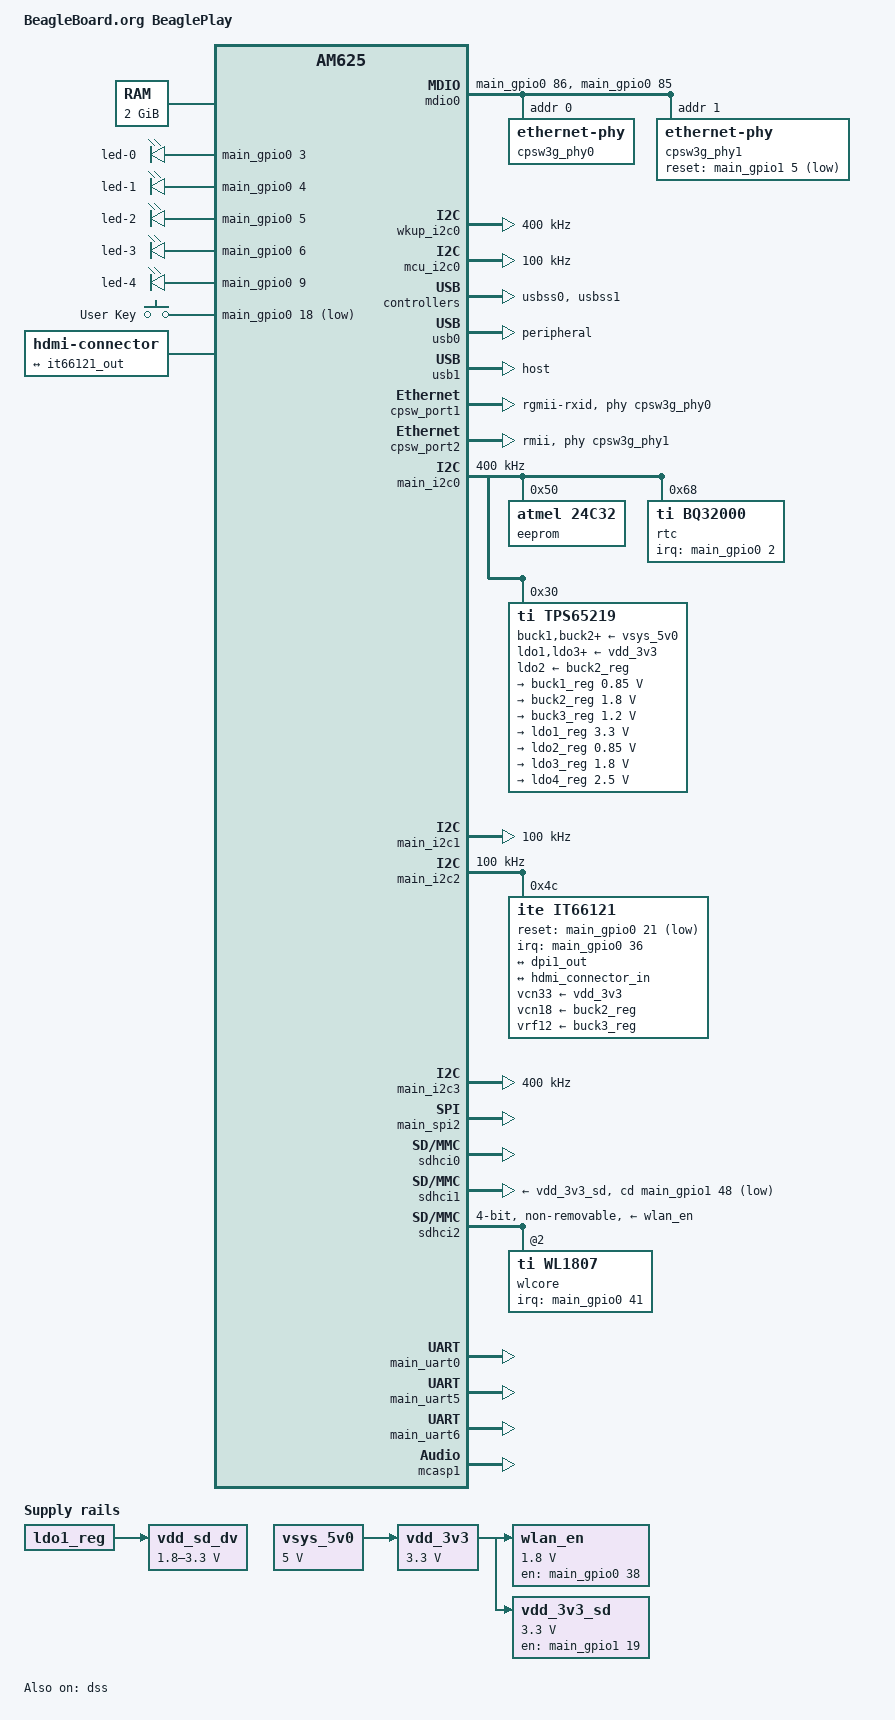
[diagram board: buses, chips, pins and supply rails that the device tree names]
/dts-v1/;
#include <dt-bindings/leds/common.h>
#include <dt-bindings/gpio/gpio.h>
#include <dt-bindings/input/input.h>
#include "k3-am625.dtsi"
/ {
	compatible = "beagle,am625-beagleplay", "ti,am625";
	model = "BeagleBoard.org BeaglePlay";
	aliases {
		ethernet0 = &cpsw_port1;
		ethernet1 = &cpsw_port2;
		gpio0 = &main_gpio0;
		gpio1 = &main_gpio1;
		gpio2 = &mcu_gpio0;
		i2c0 = &main_i2c0;
		i2c1 = &main_i2c1;
		i2c2 = &main_i2c2;
		i2c3 = &main_i2c3;
		i2c4 = &wkup_i2c0;
		i2c5 = &mcu_i2c0;
		mdio-gpio0 = &mdio0;
		mmc0 = &sdhci0;
		mmc1 = &sdhci1;
		mmc2 = &sdhci2;
		rtc0 = &rtc;
		serial0 = &main_uart5;
		serial1 = &main_uart6;
		serial2 = &main_uart0;
		usb0 = &usb0;
		usb1 = &usb1;
	};
	chosen {
		stdout-path = "serial2:115200n8";
	};
	memory@80000000 {
		device_type = "memory";
		reg = <0x00000000 0x80000000 0x00000000 0x80000000>;
	};
	reserved-memory {
		#address-cells = <2>;
		#size-cells = <2>;
		ranges;
		ramoops: ramoops@9ca00000 {
			compatible = "ramoops";
			reg = <0x00 0x9ca00000 0x00 0x00100000>;
			record-size = <0x8000>;
			console-size = <0x8000>;
			ftrace-size = <0x00>;
			pmsg-size = <0x8000>;
		};
		secure_tfa_ddr: tfa@9e780000 {
			reg = <0x00 0x9e780000 0x00 0x80000>;
			no-map;
		};
		secure_ddr: optee@9e800000 {
			reg = <0x00 0x9e800000 0x00 0x01800000>;
			no-map;
		};
		wkup_r5fss0_core0_dma_memory_region: r5f-dma-memory@9db00000 {
			compatible = "shared-dma-pool";
			reg = <0x00 0x9db00000 0x00 0xc00000>;
			no-map;
		};
	};
	vsys_5v0: regulator-1 {
		compatible = "regulator-fixed";
		regulator-name = "vsys_5v0";
		regulator-min-microvolt = <5000000>;
		regulator-max-microvolt = <5000000>;
		regulator-always-on;
		regulator-boot-on;
	};
	vdd_3v3: regulator-2 {
		compatible = "regulator-fixed";
		regulator-name = "vdd_3v3";
		regulator-min-microvolt = <3300000>;
		regulator-max-microvolt = <3300000>;
		vin-supply = <&vsys_5v0>;
		regulator-always-on;
		regulator-boot-on;
	};
	wlan_en: regulator-3 {
		compatible = "regulator-fixed";
		regulator-name = "wlan_en";
		regulator-min-microvolt = <1800000>;
		regulator-max-microvolt = <1800000>;
		enable-active-high;
		regulator-always-on;
		vin-supply = <&vdd_3v3>;
		gpio = <&main_gpio0 38 GPIO_ACTIVE_HIGH>;
		pinctrl-names = "default";
		pinctrl-0 = <&wifi_en_pins_default>;
	};
	vdd_3v3_sd: regulator-4 {
		pinctrl-names = "default";
		pinctrl-0 = <&vdd_3v3_sd_pins_default>;
		compatible = "regulator-fixed";
		regulator-name = "vdd_3v3_sd";
		regulator-min-microvolt = <3300000>;
		regulator-max-microvolt = <3300000>;
		enable-active-high;
		regulator-always-on;
		vin-supply = <&vdd_3v3>;
		gpio = <&main_gpio1 19 GPIO_ACTIVE_HIGH>;
	};
	vdd_sd_dv: regulator-5 {
		compatible = "regulator-gpio";
		regulator-name = "sd_hs200_switch";
		pinctrl-names = "default";
		pinctrl-0 = <&vdd_sd_dv_pins_default>;
		regulator-min-microvolt = <1800000>;
		regulator-max-microvolt = <3300000>;
		regulator-boot-on;
		vin-supply = <&ldo1_reg>;
		gpios = <&main_gpio1 49 GPIO_ACTIVE_HIGH>;
		states = <1800000 0x0>,
			 <3300000 0x1>;
	};
	leds {
		compatible = "gpio-leds";
		led-0 {
			gpios = <&main_gpio0 3 GPIO_ACTIVE_HIGH>;
			linux,default-trigger = "heartbeat";
			function = LED_FUNCTION_HEARTBEAT;
			default-state = "off";
		};
		led-1 {
			gpios = <&main_gpio0 4 GPIO_ACTIVE_HIGH>;
			linux,default-trigger = "disk-activity";
			function = LED_FUNCTION_DISK_ACTIVITY;
			default-state = "keep";
		};
		led-2 {
			gpios = <&main_gpio0 5 GPIO_ACTIVE_HIGH>;
			function = LED_FUNCTION_CPU;
		};
		led-3 {
			gpios = <&main_gpio0 6 GPIO_ACTIVE_HIGH>;
			function = LED_FUNCTION_LAN;
		};
		led-4 {
			gpios = <&main_gpio0 9 GPIO_ACTIVE_HIGH>;
			function = LED_FUNCTION_WLAN;
		};
	};
	gpio_keys: gpio-keys {
		compatible = "gpio-keys";
		autorepeat;
		pinctrl-names = "default";
		pinctrl-0 = <&usr_button_pins_default>;
		usr: button-usr {
			label = "User Key";
			linux,code = <BTN_0>;
			gpios = <&main_gpio0 18 GPIO_ACTIVE_LOW>;
		};
	};
	hdmi0: connector-hdmi {
		compatible = "hdmi-connector";
		label = "hdmi";
		type = "a";
		port {
			hdmi_connector_in: endpoint {
				remote-endpoint = <&it66121_out>;
			};
		};
	};
	sound {
		compatible = "simple-audio-card";
		simple-audio-card,name = "it66121 HDMI";
		simple-audio-card,format = "i2s";
		simple-audio-card,bitclock-master = <&hdmi_dailink_master>;
		simple-audio-card,frame-master = <&hdmi_dailink_master>;
		hdmi_dailink_master: simple-audio-card,cpu {
			sound-dai = <&mcasp1>;
			system-clock-direction-out;
		};
		simple-audio-card,codec {
			sound-dai = <&it66121>;
		};
	};
	mdio0: mdio {
		compatible = "virtual,mdio-gpio";
		pinctrl-names = "default";
		pinctrl-0 = <&mdio0_pins_default>;
		gpios = <&main_gpio0 86 GPIO_ACTIVE_HIGH>,  
			<&main_gpio0 85 GPIO_ACTIVE_HIGH>;  
		#address-cells = <1>;
		#size-cells = <0>;
		cpsw3g_phy0: ethernet-phy@0 {
			reg = <0>;
		};
		cpsw3g_phy1: ethernet-phy@1 {
			reg = <1>;
			reset-gpios = <&main_gpio1 5 GPIO_ACTIVE_LOW>;
			reset-assert-us = <25>;
			reset-deassert-us = <60000>;  
		};
	};
};
&main_pmx0 {
	gpio0_pins_default: gpio0-default-pins {
		pinctrl-single,pins = <
			AM62X_IOPAD(0x0004, PIN_INPUT, 7)  
			AM62X_IOPAD(0x0008, PIN_INPUT, 7)  
			AM62X_IOPAD(0x000c, PIN_INPUT, 7)  
			AM62X_IOPAD(0x0010, PIN_INPUT, 7)  
			AM62X_IOPAD(0x0014, PIN_INPUT, 7)  
			AM62X_IOPAD(0x0018, PIN_INPUT, 7)  
			AM62X_IOPAD(0x0024, PIN_INPUT, 7)  
			AM62X_IOPAD(0x0028, PIN_INPUT, 7)  
			AM62X_IOPAD(0x002c, PIN_INPUT, 7)  
			AM62X_IOPAD(0x0030, PIN_INPUT, 7)  
			AM62X_IOPAD(0x0034, PIN_INPUT, 7)  
			AM62X_IOPAD(0x0038, PIN_INPUT, 7)  
			AM62X_IOPAD(0x00a4, PIN_INPUT, 7)  
			AM62X_IOPAD(0x00ac, PIN_INPUT, 7)  
		>;
	};
	vdd_sd_dv_pins_default: vdd-sd-default-pins {
		pinctrl-single,pins = <
			AM62X_IOPAD(0x0244, PIN_OUTPUT, 7)  
		>;
	};
	usr_button_pins_default: usr-button-default-pins {
		pinctrl-single,pins = <
			AM62X_IOPAD(0x0048, PIN_INPUT, 7)  
		>;
	};
	grove_pins_default: grove-default-pins {
		pinctrl-single,pins = <
			AM62X_IOPAD(0x01e8, PIN_INPUT_PULLUP, 0)  
			AM62X_IOPAD(0x01ec, PIN_INPUT_PULLUP, 0)  
		>;
	};
	local_i2c_pins_default: local-i2c-default-pins {
		pinctrl-single,pins = <
			AM62X_IOPAD(0x01e0, PIN_INPUT_PULLUP, 0)  
			AM62X_IOPAD(0x01e4, PIN_INPUT_PULLUP, 0)  
		>;
	};
	i2c2_1v8_pins_default: i2c2-default-pins {
		pinctrl-single,pins = <
			AM62X_IOPAD(0x00b0, PIN_INPUT_PULLUP, 1)  
			AM62X_IOPAD(0x00b4, PIN_INPUT_PULLUP, 1)  
		>;
	};
	mdio0_pins_default: mdio0-default-pins {
		pinctrl-single,pins = <
			AM62X_IOPAD(0x0160, PIN_OUTPUT, 7)  
			AM62X_IOPAD(0x015c, PIN_INPUT, 7)  
		>;
	};
	rgmii1_pins_default: rgmii1-default-pins {
		pinctrl-single,pins = <
			AM62X_IOPAD(0x014c, PIN_INPUT, 0)  
			AM62X_IOPAD(0x0150, PIN_INPUT, 0)  
			AM62X_IOPAD(0x0154, PIN_INPUT, 0)  
			AM62X_IOPAD(0x0158, PIN_INPUT, 0)  
			AM62X_IOPAD(0x0148, PIN_INPUT, 0)  
			AM62X_IOPAD(0x0144, PIN_INPUT, 0)  
			AM62X_IOPAD(0x0134, PIN_OUTPUT, 0)  
			AM62X_IOPAD(0x0138, PIN_OUTPUT, 0)  
			AM62X_IOPAD(0x013c, PIN_OUTPUT, 0)  
			AM62X_IOPAD(0x0140, PIN_OUTPUT, 0)  
			AM62X_IOPAD(0x0130, PIN_OUTPUT, 0)  
			AM62X_IOPAD(0x012c, PIN_OUTPUT, 0)  
		>;
	};
	emmc_pins_default: emmc-default-pins {
		pinctrl-single,pins = <
			AM62X_IOPAD(0x0220, PIN_INPUT, 0)  
			AM62X_IOPAD(0x0218, PIN_INPUT, 0)  
			AM62X_IOPAD(0x0214, PIN_INPUT, 0)  
			AM62X_IOPAD(0x0210, PIN_INPUT, 0)  
			AM62X_IOPAD(0x020c, PIN_INPUT, 0)  
			AM62X_IOPAD(0x0208, PIN_INPUT, 0)  
			AM62X_IOPAD(0x0204, PIN_INPUT, 0)  
			AM62X_IOPAD(0x0200, PIN_INPUT, 0)  
			AM62X_IOPAD(0x01fc, PIN_INPUT, 0)  
			AM62X_IOPAD(0x01f8, PIN_INPUT, 0)  
		>;
	};
	vdd_3v3_sd_pins_default: vdd-3v3-sd-default-pins {
		pinctrl-single,pins = <
			AM62X_IOPAD(0x01c4, PIN_INPUT, 7)  
		>;
	};
	sd_pins_default: sd-default-pins {
		pinctrl-single,pins = <
			AM62X_IOPAD(0x023c, PIN_INPUT, 0)  
			AM62X_IOPAD(0x0234, PIN_INPUT, 0)  
			AM62X_IOPAD(0x0230, PIN_INPUT, 0)  
			AM62X_IOPAD(0x022c, PIN_INPUT, 0)  
			AM62X_IOPAD(0x0228, PIN_INPUT, 0)  
			AM62X_IOPAD(0x0224, PIN_INPUT, 0)  
			AM62X_IOPAD(0x0240, PIN_INPUT, 7)  
		>;
	};
	wifi_pins_default: wifi-default-pins {
		pinctrl-single,pins = <
			AM62X_IOPAD(0x0120, PIN_INPUT, 0)  
			AM62X_IOPAD(0x0118, PIN_INPUT, 0)  
			AM62X_IOPAD(0x0114, PIN_INPUT, 0)  
			AM62X_IOPAD(0x0110, PIN_INPUT, 0)  
			AM62X_IOPAD(0x010c, PIN_INPUT, 0)  
			AM62X_IOPAD(0x0108, PIN_INPUT, 0)  
			AM62X_IOPAD(0x0124, PIN_INPUT, 0)  
			AM62X_IOPAD(0x11c, PIN_INPUT, 0)  
		>;
	};
	wifi_en_pins_default: wifi-en-default-pins {
		pinctrl-single,pins = <
			AM62X_IOPAD(0x009c, PIN_OUTPUT, 7)  
		>;
	};
	wifi_wlirq_pins_default: wifi-wlirq-default-pins {
		pinctrl-single,pins = <
			AM62X_IOPAD(0x00a8, PIN_INPUT, 7)  
		>;
	};
	spe_pins_default: spe-default-pins {
		pinctrl-single,pins = <
			AM62X_IOPAD(0x0168, PIN_INPUT, 1)  
			AM62X_IOPAD(0x0180, PIN_INPUT, 1)  
			AM62X_IOPAD(0x0184, PIN_INPUT, 1)  
			AM62X_IOPAD(0x0188, PIN_INPUT, 1)  
			AM62X_IOPAD(0x017c, PIN_INPUT, 1)  
			AM62X_IOPAD(0x016c, PIN_INPUT, 1)  
			AM62X_IOPAD(0x0170, PIN_INPUT, 1)  
			AM62X_IOPAD(0x0164, PIN_INPUT, 1)  
			AM62X_IOPAD(0x018c, PIN_OUTPUT, 7)  
			AM62X_IOPAD(0x0190, PIN_INPUT, 7)  
			AM62X_IOPAD(0x01f0, PIN_OUTPUT, 5)  
		>;
	};
	mikrobus_i2c_pins_default: mikrobus-i2c-default-pins {
		pinctrl-single,pins = <
			AM62X_IOPAD(0x01d0, PIN_INPUT_PULLUP, 2)  
			AM62X_IOPAD(0x01d4, PIN_INPUT_PULLUP, 2)  
		>;
	};
	mikrobus_uart_pins_default: mikrobus-uart-default-pins {
		pinctrl-single,pins = <
			AM62X_IOPAD(0x01d8, PIN_INPUT, 1)  
			AM62X_IOPAD(0x01dc, PIN_OUTPUT, 1)  
		>;
	};
	mikrobus_spi_pins_default: mikrobus-spi-default-pins {
		pinctrl-single,pins = <
			AM62X_IOPAD(0x01b0, PIN_INPUT, 1)  
			AM62X_IOPAD(0x01ac, PIN_INPUT, 1)  
			AM62X_IOPAD(0x0194, PIN_INPUT, 1)  
			AM62X_IOPAD(0x0198, PIN_INPUT, 1)  
		>;
	};
	mikrobus_gpio_pins_default: mikrobus-gpio-default-pins {
		pinctrl-single,pins = <
			AM62X_IOPAD(0x019c, PIN_INPUT, 7)  
			AM62X_IOPAD(0x01a0, PIN_INPUT, 7)  
			AM62X_IOPAD(0x01a8, PIN_INPUT, 7)  
		>;
	};
	console_pins_default: console-default-pins {
		pinctrl-single,pins = <
			AM62X_IOPAD(0x01c8, PIN_INPUT, 0)  
			AM62X_IOPAD(0x01cc, PIN_OUTPUT, 0)  
		>;
	};
	wifi_debug_uart_pins_default: wifi-debug-uart-default-pins {
		pinctrl-single,pins = <
			AM62X_IOPAD(0x001c, PIN_INPUT, 3)  
			AM62X_IOPAD(0x0020, PIN_OUTPUT, 3)  
		>;
	};
	usb1_pins_default: usb1-default-pins {
		pinctrl-single,pins = <
			AM62X_IOPAD(0x0258, PIN_INPUT, 0)  
		>;
	};
	pmic_irq_pins_default: pmic-irq-default-pins {
		pinctrl-single,pins = <
			AM62X_IOPAD(0x01f4, PIN_INPUT_PULLUP, 0)  
		>;
	};
	hdmi_gpio_pins_default: hdmi-gpio-default-pins {
		pinctrl-single,pins = <
			AM62X_IOPAD(0x0094, PIN_INPUT_PULLUP | PIN_DEBOUNCE_CONF6, 7)  
			AM62X_IOPAD(0x0054, PIN_OUTPUT_PULLUP, 7)  
		>;
	};
	mcasp_hdmi_pins_default: mcasp-hdmi-default-pins {
		pinctrl-single,pins = <
			AM62X_IOPAD(0x0090, PIN_INPUT, 2)  
			AM62X_IOPAD(0x0098, PIN_INPUT, 2)  
			AM62X_IOPAD(0x008c, PIN_OUTPUT, 2)  
			AM62X_IOPAD(0x0088, PIN_INPUT, 2)  
			AM62X_IOPAD(0x0084, PIN_INPUT, 2)  
			AM62X_IOPAD(0x007c, PIN_INPUT, 2)  
		>;
	};
	dss0_pins_default: dss0-default-pins {
		pinctrl-single,pins = <
			AM62X_IOPAD(0x0100, PIN_OUTPUT, 0)  
			AM62X_IOPAD(0x00f8, PIN_OUTPUT, 0)  
			AM62X_IOPAD(0x0104, PIN_OUTPUT, 0)  
			AM62X_IOPAD(0x00fc, PIN_OUTPUT, 0)  
			AM62X_IOPAD(0x00b8, PIN_OUTPUT, 0)  
			AM62X_IOPAD(0x00bc, PIN_OUTPUT, 0)  
			AM62X_IOPAD(0x00c0, PIN_OUTPUT, 0)  
			AM62X_IOPAD(0x00c4, PIN_OUTPUT, 0)  
			AM62X_IOPAD(0x00c8, PIN_OUTPUT, 0)  
			AM62X_IOPAD(0x00cc, PIN_OUTPUT, 0)  
			AM62X_IOPAD(0x00d0, PIN_OUTPUT, 0)  
			AM62X_IOPAD(0x00d4, PIN_OUTPUT, 0)  
			AM62X_IOPAD(0x00d8, PIN_OUTPUT, 0)  
			AM62X_IOPAD(0x00dc, PIN_OUTPUT, 0)  
			AM62X_IOPAD(0x00e0, PIN_OUTPUT, 0)  
			AM62X_IOPAD(0x00e4, PIN_OUTPUT, 0)  
			AM62X_IOPAD(0x00e8, PIN_OUTPUT, 0)  
			AM62X_IOPAD(0x00ec, PIN_OUTPUT, 0)  
			AM62X_IOPAD(0x00f0, PIN_OUTPUT, 0)  
			AM62X_IOPAD(0x00f4, PIN_OUTPUT, 0)  
			AM62X_IOPAD(0x005c, PIN_OUTPUT, 1)  
			AM62X_IOPAD(0x0060, PIN_OUTPUT, 1)  
			AM62X_IOPAD(0x0064, PIN_OUTPUT, 1)  
			AM62X_IOPAD(0x0068, PIN_OUTPUT, 1)  
			AM62X_IOPAD(0x006c, PIN_OUTPUT, 1)  
			AM62X_IOPAD(0x0070, PIN_OUTPUT, 1)  
			AM62X_IOPAD(0x0074, PIN_OUTPUT, 1)  
			AM62X_IOPAD(0x0078, PIN_OUTPUT, 1)  
		>;
	};
};
&mcu_pmx0 {
	i2c_qwiic_pins_default: i2c-qwiic-default-pins {
		pinctrl-single,pins = <
			AM62X_MCU_IOPAD(0x0044, PIN_INPUT, 0)  
			AM62X_MCU_IOPAD(0x0048, PIN_INPUT, 0)  
		>;
	};
	gbe_pmx_obsclk: gbe-pmx-obsclk-default-pins {
		pinctrl-single,pins = <
			AM62X_MCU_IOPAD(0x0004, PIN_OUTPUT, 1)  
		>;
	};
	i2c_csi_pins_default: i2c-csi-default-pins {
		pinctrl-single,pins = <
			AM62X_MCU_IOPAD(0x004c, PIN_INPUT_PULLUP, 0)  
			AM62X_MCU_IOPAD(0x0050, PIN_INPUT_PULLUP, 0)  
		>;
	};
	wifi_32k_clk: mcu-clk-out-default-pins {
		pinctrl-single,pins = <
			AM62X_MCU_IOPAD(0x0084, PIN_OUTPUT, 0)  
		>;
	};
};
&a53_opp_table {
	opp-1400000000 {
		opp-hz = /bits/ 64 <1400000000>;
		opp-supported-hw = <0x01 0x0004>;
	};
};
&wkup_i2c0 {
	pinctrl-names = "default";
	pinctrl-0 = <&i2c_csi_pins_default>;
	clock-frequency = <400000>;
};
&mcu_i2c0 {
	pinctrl-names = "default";
	pinctrl-0 = <&i2c_qwiic_pins_default>;
	clock-frequency = <100000>;
	status = "okay";
};
&usbss0 {
	ti,vbus-divider;
	status = "okay";
};
&usb0 {
	dr_mode = "peripheral";
};
&usbss1 {
	ti,vbus-divider;
	status = "okay";
};
&usb1 {
	dr_mode = "host";
	pinctrl-names = "default";
	pinctrl-0 = <&usb1_pins_default>;
};
&cpsw3g {
	pinctrl-names = "default";
	pinctrl-0 = <&rgmii1_pins_default>, <&spe_pins_default>,
		    <&gbe_pmx_obsclk>;
	assigned-clocks = <&k3_clks 157 70>, <&k3_clks 157 20>;
	assigned-clock-parents = <&k3_clks 157 72>, <&k3_clks 157 22>;
};
&cpsw_port1 {
	phy-mode = "rgmii-rxid";
	phy-handle = <&cpsw3g_phy0>;
};
&cpsw_port2 {
	phy-mode = "rmii";
	phy-handle = <&cpsw3g_phy1>;
};
&cpsw3g_mdio {
	status = "disabled";
};
&main_gpio0 {
	pinctrl-names = "default";
	pinctrl-0 = <&gpio0_pins_default>;
	gpio-line-names = "BL_EN_3V3", "SPE_PO_EN", "RTC_INT",	 
		"USR0", "USR1", "USR2", "USR3", "", "", "USR4",	 
		"EEPROM_WP",					 
		"CSI2_CAMERA_GPIO1", "CSI2_CAMERA_GPIO2",	 
		"CC1352P7_BOOT", "CC1352P7_RSTN", "", "", "",	 
		"USR_BUTTON", "", "", "", "", "", "", "", "",	 
		"", "", "", "", "", "", "", "", "", "HDMI_INT",	 
		"", "VDD_WLAN_EN", "", "", "WL_IRQ", "GBE_INTN", 
		"", "", "", "", "", "", "", "", "", "", "", "",	 
		"", "", "", "", "", "", "", "", "", "", "", "",  
		"", "", "", "", "", "", "", "", "", "", "", "",  
		"", "", "", "", "", "",				 
		"BITBANG_MDIO_DATA", "BITBANG_MDIO_CLK",	 
		"", "", "", "", "";				 
};
&main_gpio1 {
	pinctrl-names = "default";
	pinctrl-0 = <&mikrobus_gpio_pins_default>;
	gpio-line-names = "", "", "", "", "",			 
		"SPE_RSTN", "SPE_INTN", "MIKROBUS_GPIO1_7",	 
		"MIKROBUS_GPIO1_8", "MIKROBUS_GPIO1_9",		 
		"MIKROBUS_GPIO1_10", "MIKROBUS_GPIO1_11",	 
		"MIKROBUS_GPIO1_12", "MIKROBUS_W1_GPIO0",	 
		"MIKROBUS_GPIO1_14",				 
		"", "", "", "", "VDD_3V3_SD", "", "",		 
		"MIKROBUS_GPIO1_22", "MIKROBUS_GPIO1_23",	 
		"MIKROBUS_GPIO1_24", "MIKROBUS_GPIO1_25",	 
		"", "", "", "", "", "", "", "", "", "", "", "",	 
		"", "", "", "", "", "", "", "", "", "",		 
		"SD_CD", "SD_VOLT_SEL", "", "";			 
};
&main_i2c0 {
	pinctrl-names = "default";
	pinctrl-0 = <&local_i2c_pins_default>;
	clock-frequency = <400000>;
	status = "okay";
	eeprom@50 {
		compatible = "atmel,24c32";
		reg = <0x50>;
	};
	rtc: rtc@68 {
		compatible = "ti,bq32000";
		reg = <0x68>;
		interrupt-parent = <&main_gpio0>;
		interrupts = <2 IRQ_TYPE_EDGE_FALLING>;
	};
	tps65219: pmic@30 {
		compatible = "ti,tps65219";
		reg = <0x30>;
		buck1-supply = <&vsys_5v0>;
		buck2-supply = <&vsys_5v0>;
		buck3-supply = <&vsys_5v0>;
		ldo1-supply = <&vdd_3v3>;
		ldo2-supply = <&buck2_reg>;
		ldo3-supply = <&vdd_3v3>;
		ldo4-supply = <&vdd_3v3>;
		pinctrl-names = "default";
		pinctrl-0 = <&pmic_irq_pins_default>;
		interrupt-parent = <&gic500>;
		interrupts = <GIC_SPI 224 IRQ_TYPE_LEVEL_HIGH>;
		interrupt-controller;
		#interrupt-cells = <1>;
		system-power-controller;
		ti,power-button;
		regulators {
			buck1_reg: buck1 {
				regulator-name = "VDD_CORE";
				regulator-min-microvolt = <850000>;
				regulator-max-microvolt = <850000>;
				regulator-boot-on;
				regulator-always-on;
			};
			buck2_reg: buck2 {
				regulator-name = "VDD_1V8";
				regulator-min-microvolt = <1800000>;
				regulator-max-microvolt = <1800000>;
				regulator-boot-on;
				regulator-always-on;
			};
			buck3_reg: buck3 {
				regulator-name = "VDD_1V2";
				regulator-min-microvolt = <1200000>;
				regulator-max-microvolt = <1200000>;
				regulator-boot-on;
				regulator-always-on;
			};
			ldo1_reg: ldo1 {
				regulator-name = "VDD_SD_3V3";
				regulator-min-microvolt = <3300000>;
				regulator-max-microvolt = <3300000>;
				regulator-allow-bypass;
				regulator-boot-on;
				regulator-always-on;
			};
			ldo2_reg: ldo2 {
				regulator-name = "VDDA_0V85";
				regulator-min-microvolt = <850000>;
				regulator-max-microvolt = <850000>;
				regulator-boot-on;
				regulator-always-on;
			};
			ldo3_reg: ldo3 {
				regulator-name = "VDDA_1V8";
				regulator-min-microvolt = <1800000>;
				regulator-max-microvolt = <1800000>;
				regulator-boot-on;
				regulator-always-on;
			};
			ldo4_reg: ldo4 {
				regulator-name = "VDD_2V5";
				regulator-min-microvolt = <2500000>;
				regulator-max-microvolt = <2500000>;
				regulator-boot-on;
				regulator-always-on;
			};
		};
	};
};
&main_i2c1 {
	pinctrl-names = "default";
	pinctrl-0 = <&grove_pins_default>;
	clock-frequency = <100000>;
	status = "okay";
};
&main_i2c2 {
	pinctrl-names = "default";
	pinctrl-0 = <&i2c2_1v8_pins_default>;
	clock-frequency = <100000>;
	status = "okay";
	it66121: bridge-hdmi@4c {
		compatible = "ite,it66121";
		reg = <0x4c>;
		pinctrl-names = "default";
		pinctrl-0 = <&hdmi_gpio_pins_default>;
		vcn33-supply = <&vdd_3v3>;
		vcn18-supply = <&buck2_reg>;
		vrf12-supply = <&buck3_reg>;
		reset-gpios = <&main_gpio0 21 GPIO_ACTIVE_LOW>;
		interrupt-parent = <&main_gpio0>;
		interrupts = <36 IRQ_TYPE_EDGE_FALLING>;
		#sound-dai-cells = <0>;
		ports {
			#address-cells = <1>;
			#size-cells = <0>;
			port@0 {
				reg = <0>;
				it66121_in: endpoint {
					bus-width = <24>;
					remote-endpoint = <&dpi1_out>;
				};
			};
			port@1 {
				reg = <1>;
				it66121_out: endpoint {
					remote-endpoint = <&hdmi_connector_in>;
				};
			};
		};
	};
};
&main_i2c3 {
	pinctrl-names = "default";
	pinctrl-0 = <&mikrobus_i2c_pins_default>;
	clock-frequency = <400000>;
	status = "okay";
};
&main_spi2 {
	pinctrl-names = "default";
	pinctrl-0 = <&mikrobus_spi_pins_default>;
	status = "okay";
};
&sdhci0 {
	pinctrl-names = "default";
	pinctrl-0 = <&emmc_pins_default>;
	ti,driver-strength-ohm = <50>;
	disable-wp;
	status = "okay";
};
&sdhci1 {
	pinctrl-names = "default";
	pinctrl-0 = <&sd_pins_default>;
	vmmc-supply = <&vdd_3v3_sd>;
	vqmmc-supply = <&vdd_sd_dv>;
	ti,driver-strength-ohm = <50>;
	disable-wp;
	cd-gpios = <&main_gpio1 48 GPIO_ACTIVE_LOW>;
	cd-debounce-delay-ms = <100>;
	ti,fails-without-test-cd;
	status = "okay";
};
&sdhci2 {
	vmmc-supply = <&wlan_en>;
	pinctrl-names = "default";
	pinctrl-0 = <&wifi_pins_default>, <&wifi_32k_clk>;
	bus-width = <4>;
	non-removable;
	ti,fails-without-test-cd;
	cap-power-off-card;
	keep-power-in-suspend;
	ti,driver-strength-ohm = <50>;
	assigned-clocks = <&k3_clks 157 158>;
	assigned-clock-parents = <&k3_clks 157 160>;
	#address-cells = <1>;
	#size-cells = <0>;
	status = "okay";
	wlcore: wlcore@2 {
		compatible = "ti,wl1807";
		reg = <2>;
		pinctrl-names = "default";
		pinctrl-0 = <&wifi_wlirq_pins_default>;
		interrupt-parent = <&main_gpio0>;
		interrupts = <41 IRQ_TYPE_EDGE_FALLING>;
	};
};
&main_uart0 {
	pinctrl-names = "default";
	pinctrl-0 = <&console_pins_default>;
	status = "okay";
};
&main_uart1 {
	status = "reserved";
};
&main_uart5 {
	pinctrl-names = "default";
	pinctrl-0 = <&mikrobus_uart_pins_default>;
	status = "okay";
};
&main_uart6 {
	pinctrl-names = "default";
	pinctrl-0 = <&wifi_debug_uart_pins_default>;
	status = "okay";
};
&dss {
	status = "okay";
	pinctrl-names = "default";
	pinctrl-0 = <&dss0_pins_default>;
};
&dss_ports {
	port@1 {
		reg = <1>;
		dpi1_out: endpoint {
			remote-endpoint = <&it66121_in>;
		};
	};
};
&mcasp1 {
	status = "okay";
	#sound-dai-cells = <0>;
	pinctrl-names = "default";
	pinctrl-0 = <&mcasp_hdmi_pins_default>;
	auxclk-fs-ratio = <2177>;
	op-mode = <0>;           
	tdm-slots = <2>;
	serial-dir = <   
	       1 0 0 0
	       0 0 0 0
	       0 0 0 0
	       0 0 0 0
	>;
	tx-num-evt = <32>;
	rx-num-evt = <32>;
};
